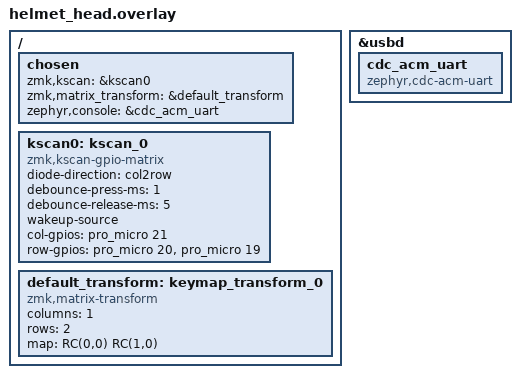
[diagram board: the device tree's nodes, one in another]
/*
 * Copyright (c) 2021 The ZMK Contributors
 *
 * SPDX-License-Identifier: MIT
 */

#include <dt-bindings/zmk/matrix_transform.h>

/ {
    chosen {
        zmk,kscan = &kscan0;
        zmk,matrix_transform = &default_transform;
        // for logging, if needed
        zephyr,console = &cdc_acm_uart;
    };

    kscan0: kscan_0 {
        compatible = "zmk,kscan-gpio-matrix";

        diode-direction = "col2row";
        debounce-press-ms = <1>;
        debounce-release-ms = <5>;
        wakeup-source;

        col-gpios
            = <&pro_micro 21 (GPIO_ACTIVE_HIGH)> // col 0
            ;

        row-gpios
            = <&pro_micro 20 (GPIO_ACTIVE_HIGH | GPIO_PULL_DOWN)> // row 0
            , <&pro_micro 19 (GPIO_ACTIVE_HIGH | GPIO_PULL_DOWN)> // row 1
            ;
    };

    default_transform: keymap_transform_0 {
        compatible = "zmk,matrix-transform";
        columns = <1>;
        rows = <2>;

        map = <
             RC(0,0) 
             RC(1,0) 
        >;
    };
};

// for logging, if needed
&usbd {
    status = "okay";
    cdc_acm_uart: cdc_acm_uart {
        compatible = "zephyr,cdc-acm-uart";
    };
};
